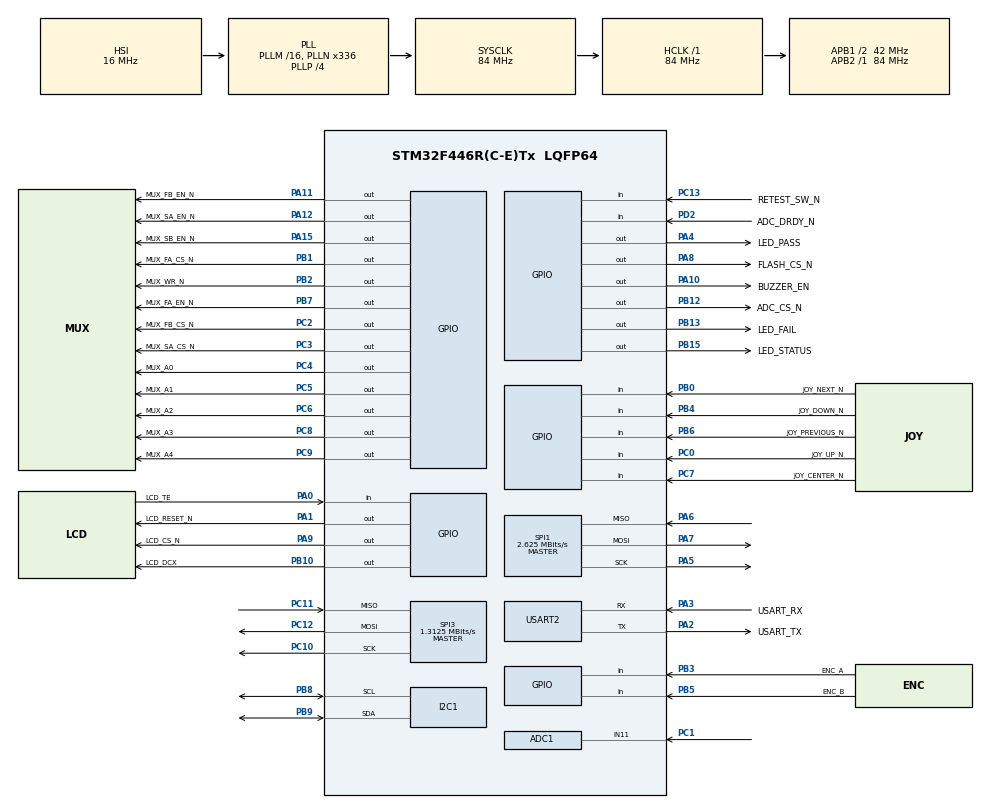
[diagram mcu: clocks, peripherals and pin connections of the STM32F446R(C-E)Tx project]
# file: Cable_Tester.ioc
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ADC1.Channel-0\#ChannelRegularConversion=ADC_CHANNEL_11
ADC1.InjNumberOfConversion=0
ADC1.NbrOfConversionFlag=1
ADC1.Rank-0\#ChannelRegularConversion=1
ADC1.SamplingTime-0\#ChannelRegularConversion=ADC_SAMPLETIME_480CYCLES
ADC1.master=1
Mcu.Family=STM32F4
Mcu.Name=STM32F446R(C-E)Tx
Mcu.Package=LQFP64
NVIC.PriorityGroup=NVIC_PRIORITYGROUP_0
PA0-WKUP.GPIO_Label=LCD_TE
PA0-WKUP.Signal=GPIO_Input
PA1.GPIO_Label=LCD_RESET_N
PA1.PinState=GPIO_PIN_SET
PA1.Signal=GPIO_Output
PA10.GPIO_Label=BUZZER_EN
PA10.Signal=GPIO_Output
PA11.GPIO_Label=MUX_FB_EN_N
PA11.PinState=GPIO_PIN_SET
PA11.Signal=GPIO_Output
PA12.GPIO_Label=MUX_SA_EN_N
PA12.PinState=GPIO_PIN_SET
PA12.Signal=GPIO_Output
PA13.GPIO_Label=TMS
PA13.Mode=Serial_Wire
PA13.Signal=SYS_JTMS-SWDIO
PA14.GPIO_Label=TCK
PA14.Mode=Serial_Wire
PA14.Signal=SYS_JTCK-SWCLK
PA15.GPIO_Label=MUX_SB_EN_N
PA15.PinState=GPIO_PIN_SET
PA15.Signal=GPIO_Output
PA2.GPIO_Label=USART_TX
PA2.Mode=Asynchronous
PA2.Signal=USART2_TX
PA3.GPIO_Label=USART_RX
PA3.Mode=Asynchronous
PA3.Signal=USART2_RX
PA4.GPIO_Label=LED_PASS
PA4.Signal=GPIO_Output
PA5.Mode=Full_Duplex_Master
PA5.Signal=SPI1_SCK
PA6.Mode=Full_Duplex_Master
PA6.Signal=SPI1_MISO
PA7.Mode=Full_Duplex_Master
PA7.Signal=SPI1_MOSI
PA8.GPIO_Label=FLASH_CS_N
PA8.GPIO_Speed=GPIO_SPEED_FREQ_HIGH
PA8.PinState=GPIO_PIN_SET
PA8.Signal=GPIO_Output
PA9.GPIO_Label=LCD_CS_N
PA9.GPIO_Speed=GPIO_SPEED_FREQ_VERY_HIGH
PA9.PinState=GPIO_PIN_SET
PA9.Signal=GPIO_Output
PB0.GPIO_Label=JOY_NEXT_N
PB0.Signal=GPIO_Input
PB1.GPIO_Label=MUX_FA_CS_N
PB1.PinState=GPIO_PIN_SET
PB1.Signal=GPIO_Output
PB10.GPIO_Label=LCD_DCX
PB10.GPIO_Speed=GPIO_SPEED_FREQ_HIGH
PB10.Signal=GPIO_Output
PB12.GPIO_Label=ADC_CS_N
PB12.GPIO_Speed=GPIO_SPEED_FREQ_HIGH
PB12.PinState=GPIO_PIN_SET
PB12.Signal=GPIO_Output
PB13.GPIO_Label=LED_FAIL
PB13.Signal=GPIO_Output
PB15.GPIO_Label=LED_STATUS
PB15.Signal=GPIO_Output
PB2.GPIO_Label=MUX_WR_N
PB2.PinState=GPIO_PIN_SET
PB2.Signal=GPIO_Output
PB3.GPIO_Label=ENC_A
PB3.GPIO_PuPd=GPIO_PULLUP
PB3.Signal=GPIO_Input
PB4.GPIO_Label=JOY_DOWN_N
PB4.Signal=GPIO_Input
PB5.GPIO_Label=ENC_B
PB5.GPIO_PuPd=GPIO_PULLUP
PB5.Signal=GPIO_Input
PB6.GPIO_Label=JOY_PREVIOUS_N
PB6.Signal=GPIO_Input
PB7.GPIO_Label=MUX_FA_EN_N
PB7.PinState=GPIO_PIN_SET
PB7.Signal=GPIO_Output
PB8.Mode=I2C
PB8.Signal=I2C1_SCL
PB9.Mode=I2C
PB9.Signal=I2C1_SDA
PC0.GPIO_Label=JOY_UP_N
PC0.Signal=GPIO_Input
PC1.Signal=ADCx_IN11
PC10.Mode=Full_Duplex_Master
PC10.Signal=SPI3_SCK
PC11.Mode=Full_Duplex_Master
PC11.Signal=SPI3_MISO
PC12.Mode=Full_Duplex_Master
PC12.Signal=SPI3_MOSI
PC13.GPIO_Label=RETEST_SW_N
PC13.GPIO_PuPd=GPIO_PULLUP
PC13.Signal=GPIO_Input
PC14-OSC32_IN.Mode=LSE-External-Oscillator
PC14-OSC32_IN.Signal=RCC_OSC32_IN
PC15-OSC32_OUT.Mode=LSE-External-Oscillator
PC15-OSC32_OUT.Signal=RCC_OSC32_OUT
PC2.GPIO_Label=MUX_FB_CS_N
PC2.PinState=GPIO_PIN_SET
PC2.Signal=GPIO_Output
PC3.GPIO_Label=MUX_SA_CS_N
PC3.PinState=GPIO_PIN_SET
PC3.Signal=GPIO_Output
PC4.GPIO_Label=MUX_A0
PC4.Signal=GPIO_Output
PC5.GPIO_Label=MUX_A1
PC5.Signal=GPIO_Output
PC6.GPIO_Label=MUX_A2
PC6.Signal=GPIO_Output
PC7.GPIO_Label=JOY_CENTER_N
PC7.Signal=GPIO_Input
PC8.GPIO_Label=MUX_A3
PC8.Signal=GPIO_Output
PC9.GPIO_Label=MUX_A4
PC9.Signal=GPIO_Output
PD2.GPIO_Label=ADC_DRDY_N
PD2.Signal=GPIO_Input
PH0-OSC_IN.Mode=HSE-External-Oscillator
PH0-OSC_IN.Signal=RCC_OSC_IN
PH1-OSC_OUT.Mode=HSE-External-Oscillator
PH1-OSC_OUT.Signal=RCC_OSC_OUT
ProjectManager.HeapSize=0x200
ProjectManager.StackSize=0x400
ProjectManager.TargetToolchain=STM32CubeIDE
RCC.48MHZClocksFreq_Value=84000000
RCC.AHBFreq_Value=84000000
RCC.APB1CLKDivider=RCC_HCLK_DIV2
RCC.APB1Freq_Value=42000000
RCC.APB1TimFreq_Value=84000000
RCC.APB2Freq_Value=84000000
RCC.APB2TimFreq_Value=84000000
RCC.CortexFreq_Value=84000000
RCC.FLatency-AdvancedSettings=FLASH_LATENCY_2
RCC.HCLKFreq_Value=84000000
RCC.HSE_VALUE=8000000
RCC.HSI_VALUE=16000000
RCC.PLLN=336
RCC.PLLP=RCC_PLLP_DIV4
RCC.SYSCLKFreq_VALUE=84000000
RCC.SYSCLKSource=RCC_SYSCLKSOURCE_PLLCLK
RCC.USBFreq_Value=168000000
RCC.VCOOutputFreq_Value=336000000
SH.ADCx_IN11.0=ADC1_IN11,IN11
SPI1.BaudRatePrescaler=SPI_BAUDRATEPRESCALER_32
SPI1.CalculateBaudRate=2.625 MBits/s
SPI1.Direction=SPI_DIRECTION_2LINES
SPI1.Mode=SPI_MODE_MASTER
SPI1.VirtualType=VM_MASTER
SPI3.BaudRatePrescaler=SPI_BAUDRATEPRESCALER_32
SPI3.CLKPhase=SPI_PHASE_2EDGE
SPI3.CalculateBaudRate=1.3125 MBits/s
SPI3.Direction=SPI_DIRECTION_2LINES
SPI3.Mode=SPI_MODE_MASTER
SPI3.VirtualType=VM_MASTER
USART2.VirtualMode=VM_ASYNC
board=NUCLEO-F446RE

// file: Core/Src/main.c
/* USER CODE BEGIN Header */
/**
  ******************************************************************************
  * @file           : main.c
  * @brief          : Main program body
  ******************************************************************************
  * @attention
  *
  * Copyright (c) 2026 STMicroelectronics.
  * All rights reserved.
  *
  * This software is licensed under terms that can be found in the LICENSE file
  * in the root directory of this software component.
  * If no LICENSE file comes with this software, it is provided AS-IS.
  *
  ******************************************************************************
  */
/* USER CODE END Header */
#include "main.h"

ADC_HandleTypeDef hadc1;

I2C_HandleTypeDef hi2c1;

SPI_HandleTypeDef hspi1;
SPI_HandleTypeDef hspi3;

UART_HandleTypeDef huart2;

void SystemClock_Config(void);
static void MX_GPIO_Init(void);
static void MX_USART2_UART_Init(void);
static void MX_ADC1_Init(void);
static void MX_SPI1_Init(void);
static void MX_SPI3_Init(void);
static void MX_I2C1_Init(void);

int main(void)
{

  /* MCU Configuration--------------------------------------------------------*/

  /* Reset of all peripherals, Initializes the Flash interface and the Systick. */
  HAL_Init();

  /* Configure the system clock */
  SystemClock_Config();

  /* Initialize all configured peripherals */
  MX_GPIO_Init();
  MX_USART2_UART_Init();
  MX_ADC1_Init();
  MX_SPI1_Init();
  MX_SPI3_Init();
  MX_I2C1_Init();
  /* USER CODE BEGIN 2 */

if (!Relay_Init())
{
    // Initialization failed: do not start a cable test.
    Error_Handler();
}

  /* USER CODE END 2 */

  /* Infinite loop */
  while (1)
  {

  }
}

void SystemClock_Config(void)
{
  RCC_OscInitTypeDef RCC_OscInitStruct = {0};
  RCC_ClkInitTypeDef RCC_ClkInitStruct = {0};

  /** Configure the main internal regulator output voltage
  */
  __HAL_RCC_PWR_CLK_ENABLE();
  __HAL_PWR_VOLTAGESCALING_CONFIG(PWR_REGULATOR_VOLTAGE_SCALE3);

  /** Initializes the RCC Oscillators according to the specified parameters
  * in the RCC_OscInitTypeDef structure.
  */
  RCC_OscInitStruct.OscillatorType = RCC_OSCILLATORTYPE_HSI;
  RCC_OscInitStruct.HSIState = RCC_HSI_ON;
  RCC_OscInitStruct.HSICalibrationValue = RCC_HSICALIBRATION_DEFAULT;
  RCC_OscInitStruct.PLL.PLLState = RCC_PLL_ON;
  RCC_OscInitStruct.PLL.PLLSource = RCC_PLLSOURCE_HSI;
  RCC_OscInitStruct.PLL.PLLM = 16;
  RCC_OscInitStruct.PLL.PLLN = 336;
  RCC_OscInitStruct.PLL.PLLP = RCC_PLLP_DIV4;
  RCC_OscInitStruct.PLL.PLLQ = 2;
  RCC_OscInitStruct.PLL.PLLR = 2;
  if (HAL_RCC_OscConfig(&RCC_OscInitStruct) != HAL_OK)
  {
    Error_Handler();
  }

  /** Initializes the CPU, AHB and APB buses clocks
  */
  RCC_ClkInitStruct.ClockType = RCC_CLOCKTYPE_HCLK|RCC_CLOCKTYPE_SYSCLK
                              |RCC_CLOCKTYPE_PCLK1|RCC_CLOCKTYPE_PCLK2;
  RCC_ClkInitStruct.SYSCLKSource = RCC_SYSCLKSOURCE_PLLCLK;
  RCC_ClkInitStruct.AHBCLKDivider = RCC_SYSCLK_DIV1;
  RCC_ClkInitStruct.APB1CLKDivider = RCC_HCLK_DIV2;
  RCC_ClkInitStruct.APB2CLKDivider = RCC_HCLK_DIV1;

  if (HAL_RCC_ClockConfig(&RCC_ClkInitStruct, FLASH_LATENCY_2) != HAL_OK)
  {
    Error_Handler();
  }
}

static void MX_ADC1_Init(void)
{

  ADC_ChannelConfTypeDef sConfig = {0};

  /** Configure the global features of the ADC (Clock, Resolution, Data Alignment and number of conversion)
  */
  hadc1.Instance = ADC1;
  hadc1.Init.ClockPrescaler = ADC_CLOCK_SYNC_PCLK_DIV4;
  hadc1.Init.Resolution = ADC_RESOLUTION_12B;
  hadc1.Init.ScanConvMode = DISABLE;
  hadc1.Init.ContinuousConvMode = DISABLE;
  hadc1.Init.DiscontinuousConvMode = DISABLE;
  hadc1.Init.ExternalTrigConvEdge = ADC_EXTERNALTRIGCONVEDGE_NONE;
  hadc1.Init.ExternalTrigConv = ADC_SOFTWARE_START;
  hadc1.Init.DataAlign = ADC_DATAALIGN_RIGHT;
  hadc1.Init.NbrOfConversion = 1;
  hadc1.Init.DMAContinuousRequests = DISABLE;
  hadc1.Init.EOCSelection = ADC_EOC_SINGLE_CONV;
  if (HAL_ADC_Init(&hadc1) != HAL_OK)
  {
    Error_Handler();
  }

  /** Configure for the selected ADC regular channel its corresponding rank in the sequencer and its sample time.
  */
  sConfig.Channel = ADC_CHANNEL_11;
  sConfig.Rank = 1;
  sConfig.SamplingTime = ADC_SAMPLETIME_480CYCLES;
  if (HAL_ADC_ConfigChannel(&hadc1, &sConfig) != HAL_OK)
  {
    Error_Handler();
  }

}

static void MX_I2C1_Init(void)
{

  hi2c1.Instance = I2C1;
  hi2c1.Init.ClockSpeed = 100000;
  hi2c1.Init.DutyCycle = I2C_DUTYCYCLE_2;
  hi2c1.Init.OwnAddress1 = 0;
  hi2c1.Init.AddressingMode = I2C_ADDRESSINGMODE_7BIT;
  hi2c1.Init.DualAddressMode = I2C_DUALADDRESS_DISABLE;
  hi2c1.Init.OwnAddress2 = 0;
  hi2c1.Init.GeneralCallMode = I2C_GENERALCALL_DISABLE;
  hi2c1.Init.NoStretchMode = I2C_NOSTRETCH_DISABLE;
  if (HAL_I2C_Init(&hi2c1) != HAL_OK)
  {
    Error_Handler();
  }

}

static void MX_SPI1_Init(void)
{

  /* SPI1 parameter configuration*/
  hspi1.Instance = SPI1;
  hspi1.Init.Mode = SPI_MODE_MASTER;
  hspi1.Init.Direction = SPI_DIRECTION_2LINES;
  hspi1.Init.DataSize = SPI_DATASIZE_8BIT;
  hspi1.Init.CLKPolarity = SPI_POLARITY_LOW;
  hspi1.Init.CLKPhase = SPI_PHASE_1EDGE;
  hspi1.Init.NSS = SPI_NSS_SOFT;
  hspi1.Init.BaudRatePrescaler = SPI_BAUDRATEPRESCALER_32;
  hspi1.Init.FirstBit = SPI_FIRSTBIT_MSB;
  hspi1.Init.TIMode = SPI_TIMODE_DISABLE;
  hspi1.Init.CRCCalculation = SPI_CRCCALCULATION_DISABLE;
  hspi1.Init.CRCPolynomial = 10;
  if (HAL_SPI_Init(&hspi1) != HAL_OK)
  {
    Error_Handler();
  }

}

static void MX_SPI3_Init(void)
{

  /* SPI3 parameter configuration*/
  hspi3.Instance = SPI3;
  hspi3.Init.Mode = SPI_MODE_MASTER;
  hspi3.Init.Direction = SPI_DIRECTION_2LINES;
  hspi3.Init.DataSize = SPI_DATASIZE_8BIT;
  hspi3.Init.CLKPolarity = SPI_POLARITY_LOW;
  hspi3.Init.CLKPhase = SPI_PHASE_2EDGE;
  hspi3.Init.NSS = SPI_NSS_SOFT;
  hspi3.Init.BaudRatePrescaler = SPI_BAUDRATEPRESCALER_32;
  hspi3.Init.FirstBit = SPI_FIRSTBIT_MSB;
  hspi3.Init.TIMode = SPI_TIMODE_DISABLE;
  hspi3.Init.CRCCalculation = SPI_CRCCALCULATION_DISABLE;
  hspi3.Init.CRCPolynomial = 10;
  if (HAL_SPI_Init(&hspi3) != HAL_OK)
  {
    Error_Handler();
  }

}

static void MX_USART2_UART_Init(void)
{

  huart2.Instance = USART2;
  huart2.Init.BaudRate = 115200;
  huart2.Init.WordLength = UART_WORDLENGTH_8B;
  huart2.Init.StopBits = UART_STOPBITS_1;
  huart2.Init.Parity = UART_PARITY_NONE;
  huart2.Init.Mode = UART_MODE_TX_RX;
  huart2.Init.HwFlowCtl = UART_HWCONTROL_NONE;
  huart2.Init.OverSampling = UART_OVERSAMPLING_16;
  if (HAL_UART_Init(&huart2) != HAL_OK)
  {
    Error_Handler();
  }

}

static void MX_GPIO_Init(void)
{
  GPIO_InitTypeDef GPIO_InitStruct = {0};

  /* GPIO Ports Clock Enable */
  __HAL_RCC_GPIOC_CLK_ENABLE();
  __HAL_RCC_GPIOH_CLK_ENABLE();
  __HAL_RCC_GPIOA_CLK_ENABLE();
  __HAL_RCC_GPIOB_CLK_ENABLE();
  __HAL_RCC_GPIOD_CLK_ENABLE();

  /*Configure GPIO pin Output Level */
  HAL_GPIO_WritePin(GPIOC, MUX_FB_CS_N_Pin|MUX_SA_CS_N_Pin, GPIO_PIN_SET);

  /*Configure GPIO pin Output Level */
  HAL_GPIO_WritePin(GPIOA, LCD_RESET_N_Pin|FLASH_CS_N_Pin|LCD_CS_N_Pin|MUX_FB_EN_N_Pin
                          |MUX_SA_EN_N_Pin|MUX_SB_EN_N_Pin, GPIO_PIN_SET);

  /*Configure GPIO pin Output Level */
  HAL_GPIO_WritePin(GPIOA, LED_PASS_Pin|BUZZER_EN_Pin, GPIO_PIN_RESET);

  /*Configure GPIO pin Output Level */
  HAL_GPIO_WritePin(GPIOC, MUX_A0_Pin|MUX_A1_Pin|MUX_A2_Pin|MUX_A3_Pin
                          |MUX_A4_Pin, GPIO_PIN_RESET);

  /*Configure GPIO pin Output Level */
  HAL_GPIO_WritePin(GPIOB, MUX_FA_CS_N_Pin|MUX_WR_N_Pin|ADC_CS_N_Pin|MUX_FA_EN_N_Pin, GPIO_PIN_SET);

  /*Configure GPIO pin Output Level */
  HAL_GPIO_WritePin(GPIOB, LCD_DCX_Pin|LED_FAIL_Pin|LED_STATUS_Pin, GPIO_PIN_RESET);

  /*Configure GPIO pin : RETEST_SW_N_Pin */
  GPIO_InitStruct.Pin = RETEST_SW_N_Pin;
  GPIO_InitStruct.Mode = GPIO_MODE_INPUT;
  GPIO_InitStruct.Pull = GPIO_PULLUP;
  HAL_GPIO_Init(RETEST_SW_N_GPIO_Port, &GPIO_InitStruct);

  /*Configure GPIO pins : JOY_UP_N_Pin JOY_CENTER_N_Pin */
  GPIO_InitStruct.Pin = JOY_UP_N_Pin|JOY_CENTER_N_Pin;
  GPIO_InitStruct.Mode = GPIO_MODE_INPUT;
  GPIO_InitStruct.Pull = GPIO_NOPULL;
  HAL_GPIO_Init(GPIOC, &GPIO_InitStruct);

  /*Configure GPIO pins : MUX_FB_CS_N_Pin MUX_SA_CS_N_Pin MUX_A0_Pin MUX_A1_Pin
                           MUX_A2_Pin MUX_A3_Pin MUX_A4_Pin */
  GPIO_InitStruct.Pin = MUX_FB_CS_N_Pin|MUX_SA_CS_N_Pin|MUX_A0_Pin|MUX_A1_Pin
                          |MUX_A2_Pin|MUX_A3_Pin|MUX_A4_Pin;
  GPIO_InitStruct.Mode = GPIO_MODE_OUTPUT_PP;
  GPIO_InitStruct.Pull = GPIO_NOPULL;
  GPIO_InitStruct.Speed = GPIO_SPEED_FREQ_LOW;
  HAL_GPIO_Init(GPIOC, &GPIO_InitStruct);

  /*Configure GPIO pin : LCD_TE_Pin */
  GPIO_InitStruct.Pin = LCD_TE_Pin;
  GPIO_InitStruct.Mode = GPIO_MODE_INPUT;
  GPIO_InitStruct.Pull = GPIO_NOPULL;
  HAL_GPIO_Init(LCD_TE_GPIO_Port, &GPIO_InitStruct);

  /*Configure GPIO pins : LCD_RESET_N_Pin LED_PASS_Pin BUZZER_EN_Pin MUX_FB_EN_N_Pin
                           MUX_SA_EN_N_Pin MUX_SB_EN_N_Pin */
  GPIO_InitStruct.Pin = LCD_RESET_N_Pin|LED_PASS_Pin|BUZZER_EN_Pin|MUX_FB_EN_N_Pin
                          |MUX_SA_EN_N_Pin|MUX_SB_EN_N_Pin;
  GPIO_InitStruct.Mode = GPIO_MODE_OUTPUT_PP;
  GPIO_InitStruct.Pull = GPIO_NOPULL;
  GPIO_InitStruct.Speed = GPIO_SPEED_FREQ_LOW;
  HAL_GPIO_Init(GPIOA, &GPIO_InitStruct);

  /*Configure GPIO pins : JOY_NEXT_N_Pin JOY_DOWN_N_Pin JOY_PREVIOUS_N_Pin */
  GPIO_InitStruct.Pin = JOY_NEXT_N_Pin|JOY_DOWN_N_Pin|JOY_PREVIOUS_N_Pin;
  GPIO_InitStruct.Mode = GPIO_MODE_INPUT;
  GPIO_InitStruct.Pull = GPIO_NOPULL;
  HAL_GPIO_Init(GPIOB, &GPIO_InitStruct);

  /*Configure GPIO pins : MUX_FA_CS_N_Pin MUX_WR_N_Pin LED_FAIL_Pin LED_STATUS_Pin
                           MUX_FA_EN_N_Pin */
  GPIO_InitStruct.Pin = MUX_FA_CS_N_Pin|MUX_WR_N_Pin|LED_FAIL_Pin|LED_STATUS_Pin
                          |MUX_FA_EN_N_Pin;
  GPIO_InitStruct.Mode = GPIO_MODE_OUTPUT_PP;
  GPIO_InitStruct.Pull = GPIO_NOPULL;
  GPIO_InitStruct.Speed = GPIO_SPEED_FREQ_LOW;
  HAL_GPIO_Init(GPIOB, &GPIO_InitStruct);

  /*Configure GPIO pins : LCD_DCX_Pin ADC_CS_N_Pin */
  GPIO_InitStruct.Pin = LCD_DCX_Pin|ADC_CS_N_Pin;
  GPIO_InitStruct.Mode = GPIO_MODE_OUTPUT_PP;
  GPIO_InitStruct.Pull = GPIO_NOPULL;
  GPIO_InitStruct.Speed = GPIO_SPEED_FREQ_HIGH;
  HAL_GPIO_Init(GPIOB, &GPIO_InitStruct);

  /*Configure GPIO pin : FLASH_CS_N_Pin */
  GPIO_InitStruct.Pin = FLASH_CS_N_Pin;
  GPIO_InitStruct.Mode = GPIO_MODE_OUTPUT_PP;
  GPIO_InitStruct.Pull = GPIO_NOPULL;
  GPIO_InitStruct.Speed = GPIO_SPEED_FREQ_HIGH;
  HAL_GPIO_Init(FLASH_CS_N_GPIO_Port, &GPIO_InitStruct);

  /*Configure GPIO pin : LCD_CS_N_Pin */
  GPIO_InitStruct.Pin = LCD_CS_N_Pin;
  GPIO_InitStruct.Mode = GPIO_MODE_OUTPUT_PP;
  GPIO_InitStruct.Pull = GPIO_NOPULL;
  GPIO_InitStruct.Speed = GPIO_SPEED_FREQ_VERY_HIGH;
  HAL_GPIO_Init(LCD_CS_N_GPIO_Port, &GPIO_InitStruct);

  /*Configure GPIO pin : ADC_DRDY_N_Pin */
  GPIO_InitStruct.Pin = ADC_DRDY_N_Pin;
  GPIO_InitStruct.Mode = GPIO_MODE_INPUT;
  GPIO_InitStruct.Pull = GPIO_NOPULL;
  HAL_GPIO_Init(ADC_DRDY_N_GPIO_Port, &GPIO_InitStruct);

  /*Configure GPIO pins : ENC_A_Pin ENC_B_Pin */
  GPIO_InitStruct.Pin = ENC_A_Pin|ENC_B_Pin;
  GPIO_InitStruct.Mode = GPIO_MODE_INPUT;
  GPIO_InitStruct.Pull = GPIO_PULLUP;
  HAL_GPIO_Init(GPIOB, &GPIO_InitStruct);

}

void Error_Handler(void)
{
  __disable_irq();
  while (1)
  {
  }
}
